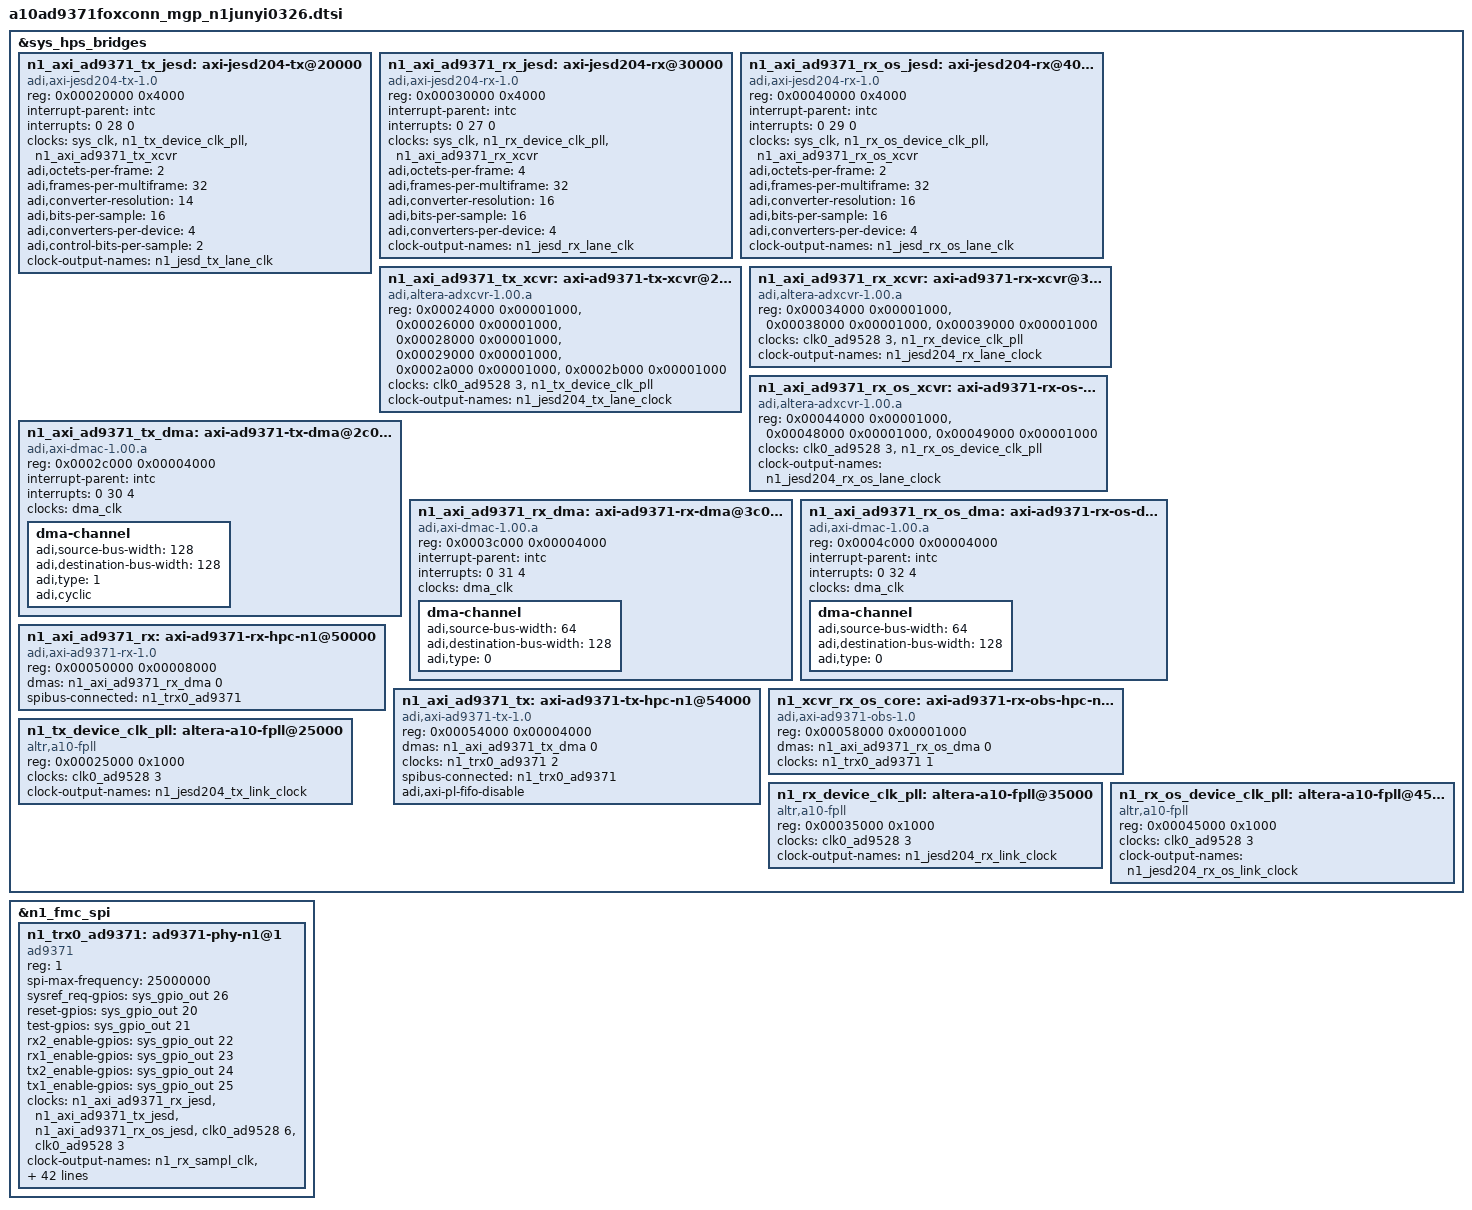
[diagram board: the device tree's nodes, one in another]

&sys_hps_bridges {

		/*n1_fmc_spi: spi@40 {
			compatible = "altr,spi-1.0";
			reg = <0x00000040 0x00000020>;
			interrupt-parent = <&intc>;
			interrupts = <0 26 4>;
			#address-cells = <0x1>;
			#size-cells = <0x0>;
		};*/

		n1_axi_ad9371_tx_jesd: axi-jesd204-tx@20000 {
			compatible = "adi,axi-jesd204-tx-1.0";
			reg = <0x00020000 0x4000>;

			interrupt-parent = <&intc>;
			interrupts = <0 28 0>;

			clocks = <&sys_clk>, <&n1_tx_device_clk_pll>, <&n1_axi_ad9371_tx_xcvr>;
			clock-names = "s_axi_aclk", "device_clk", "lane_clk";

			adi,octets-per-frame = <2>;
			adi,frames-per-multiframe = <32>;
			adi,converter-resolution = <14>;
			adi,bits-per-sample = <16>;
			adi,converters-per-device = <4>;
			adi,control-bits-per-sample = <2>;

			#clock-cells = <0>;
			clock-output-names = "n1_jesd_tx_lane_clk";
		};

		n1_axi_ad9371_rx_jesd: axi-jesd204-rx@30000 {
			compatible = "adi,axi-jesd204-rx-1.0";
			reg = <0x00030000 0x4000>;

			interrupt-parent = <&intc>;
			interrupts = <0 27 0>;

			clocks = <&sys_clk>, <&n1_rx_device_clk_pll>, <&n1_axi_ad9371_rx_xcvr>;
			clock-names = "s_axi_aclk", "device_clk", "lane_clk";

			adi,octets-per-frame = <4>;
			adi,frames-per-multiframe = <32>;
			adi,converter-resolution = <16>;
			adi,bits-per-sample = <16>;
			adi,converters-per-device = <4>;

			#clock-cells = <0>;
			clock-output-names = "n1_jesd_rx_lane_clk";
		};

		n1_axi_ad9371_rx_os_jesd: axi-jesd204-rx@40000 {
			compatible = "adi,axi-jesd204-rx-1.0";
			reg = <0x00040000 0x4000>;

			interrupt-parent = <&intc>;
			interrupts = <0 29 0>;

			clocks = <&sys_clk>, <&n1_rx_os_device_clk_pll>, <&n1_axi_ad9371_rx_os_xcvr>;
			clock-names = "s_axi_aclk", "device_clk", "lane_clk";

			adi,octets-per-frame = <2>;
			adi,frames-per-multiframe = <32>;
			adi,converter-resolution = <16>;
			adi,bits-per-sample = <16>;
			adi,converters-per-device = <4>;

			#clock-cells = <0>;
			clock-output-names = "n1_jesd_rx_os_lane_clk";
		};

		n1_axi_ad9371_tx_xcvr: axi-ad9371-tx-xcvr@24000 {
			compatible = "adi,altera-adxcvr-1.00.a";
			reg = <0x00024000 0x00001000>,
				<0x00026000 0x00001000>,
				<0x00028000 0x00001000>,
				<0x00029000 0x00001000>,
				<0x0002a000 0x00001000>,
				<0x0002b000 0x00001000>;
			reg-names = "adxcvr", "atx-pll", "adxcfg-0", "adxcfg-1", "adxcfg-2", "adxcfg-3";

			clocks = <&clk0_ad9528 3>, <&n1_tx_device_clk_pll>;
			clock-names = "ref", "link";

			#clock-cells = <0>;
			clock-output-names = "n1_jesd204_tx_lane_clock";
		};

		n1_axi_ad9371_rx_xcvr: axi-ad9371-rx-xcvr@34000 {
			compatible = "adi,altera-adxcvr-1.00.a";
			reg = <0x00034000 0x00001000>,
				<0x00038000 0x00001000>,
				<0x00039000 0x00001000>;
			reg-names = "adxcvr", "adxcfg-0", "adxcfg-1";

			clocks = <&clk0_ad9528 3>, <&n1_rx_device_clk_pll>;
			clock-names = "ref", "link";

			#clock-cells = <0>;
			clock-output-names = "n1_jesd204_rx_lane_clock";
		};

		n1_axi_ad9371_rx_os_xcvr: axi-ad9371-rx-os-xcvr@44000 {
			compatible = "adi,altera-adxcvr-1.00.a";
			reg = <0x00044000 0x00001000>,
				<0x00048000 0x00001000>,
				<0x00049000 0x00001000>;
			reg-names = "adxcvr", "adxcfg-0", "adxcfg-1";

			clocks = <&clk0_ad9528 3>, <&n1_rx_os_device_clk_pll>;
			clock-names = "ref", "link";

			#clock-cells = <0>;
			clock-output-names = "n1_jesd204_rx_os_lane_clock";
		};

		n1_axi_ad9371_tx_dma: axi-ad9371-tx-dma@2c000 {
			compatible = "adi,axi-dmac-1.00.a";
			reg = <0x0002c000 0x00004000>;
			interrupt-parent = <&intc>;
			interrupts = <0 30 4>;
			#dma-cells = <1>;
			clocks = <&dma_clk>;

			dma-channel {
				adi,source-bus-width = <128>;
				adi,destination-bus-width = <128>;
				adi,type = <1>;
				adi,cyclic;
			};
		};

		n1_axi_ad9371_rx_dma: axi-ad9371-rx-dma@3c000 {
			compatible = "adi,axi-dmac-1.00.a";
			reg = <0x0003c000 0x00004000>;
			interrupt-parent = <&intc>;
			interrupts = <0 31 4>;
			#dma-cells = <1>;
			clocks = <&dma_clk>;

			dma-channel {
				adi,source-bus-width = <64>;
				adi,destination-bus-width = <128>;
				adi,type = <0>;
			};
		};

		n1_axi_ad9371_rx_os_dma: axi-ad9371-rx-os-dma@4c000 {
			compatible = "adi,axi-dmac-1.00.a";
			reg = <0x0004c000 0x00004000>;
			interrupt-parent = <&intc>;
			interrupts = <0 32 4>;
			#dma-cells = <1>;
			clocks = <&dma_clk>;

			dma-channel {
				adi,source-bus-width = <64>;
				adi,destination-bus-width = <128>;
				adi,type = <0>;
			};
		};

		n1_axi_ad9371_rx: axi-ad9371-rx-hpc-n1@50000 {
			compatible = "adi,axi-ad9371-rx-1.0";
			reg = <0x00050000 0x00008000>;
			dmas = <&n1_axi_ad9371_rx_dma 0>;
			dma-names = "rx";
			spibus-connected = <&n1_trx0_ad9371>;
		};

		n1_axi_ad9371_tx: axi-ad9371-tx-hpc-n1@54000 {
			compatible = "adi,axi-ad9371-tx-1.0";
			reg = <0x00054000 0x00004000>;
			dmas = <&n1_axi_ad9371_tx_dma 0>;
			dma-names = "tx";
			clocks = <&n1_trx0_ad9371 2>;
			clock-names = "sampl_clk";
			spibus-connected = <&n1_trx0_ad9371>;
			//adi,axi-pl-fifo-enable;
			adi,axi-pl-fifo-disable;
		};

		n1_xcvr_rx_os_core: axi-ad9371-rx-obs-hpc-n1@58000 {
			compatible = "adi,axi-ad9371-obs-1.0";
			reg = <0x00058000 0x00001000>;
			dmas = <&n1_axi_ad9371_rx_os_dma 0>;
			dma-names = "rx";
			clocks = <&n1_trx0_ad9371 1>;
			clock-names = "sampl_clk";
		};

		n1_tx_device_clk_pll: altera-a10-fpll@25000 {
			compatible = "altr,a10-fpll";
			reg = <0x00025000 0x1000>;
			clocks = <&clk0_ad9528 3>;

			#clock-cells = <0>;
			clock-output-names = "n1_jesd204_tx_link_clock";
		};

		n1_rx_device_clk_pll: altera-a10-fpll@35000 {
			compatible = "altr,a10-fpll";
			reg = <0x00035000 0x1000>;
			clocks = <&clk0_ad9528 3>;

			#clock-cells = <0>;
			clock-output-names = "n1_jesd204_rx_link_clock";
		};

		n1_rx_os_device_clk_pll: altera-a10-fpll@45000 {
			compatible = "altr,a10-fpll";
			reg = <0x00045000 0x1000>;
			clocks = <&clk0_ad9528 3>;

			#clock-cells = <0>;
			clock-output-names = "n1_jesd204_rx_os_link_clock";
		};
};

&n1_fmc_spi {

	n1_trx0_ad9371: ad9371-phy-n1@1 {
		#address-cells = <1>;
		#size-cells = <0>;
		#clock-cells = <1>;
		compatible = "ad9371";

		reg = <1>;
		spi-max-frequency = <25000000>;

		sysref_req-gpios = <&sys_gpio_out 26 0>;
		reset-gpios = <&sys_gpio_out 20 0>;
		test-gpios = <&sys_gpio_out 21 0>;
		rx2_enable-gpios = <&sys_gpio_out 22 0>;
		rx1_enable-gpios = <&sys_gpio_out 23 0>;
		tx2_enable-gpios = <&sys_gpio_out 24 0>;
		tx1_enable-gpios = <&sys_gpio_out 25 0>;

		clocks = <&n1_axi_ad9371_rx_jesd>, <&n1_axi_ad9371_tx_jesd>, <&n1_axi_ad9371_rx_os_jesd>, <&clk0_ad9528 6>, <&clk0_ad9528 3>;
		clock-names = "jesd_rx_clk", "jesd_tx_clk", "jesd_rx_os_clk", "dev_clk", "fmc_clk";
		clock-output-names = "n1_rx_sampl_clk", "n1_rx_os_sampl_clk", "n1_tx_sampl_clk";

		adi,clocks-clk-pll-vco-freq_khz = <9830400>;
		adi,clocks-device-clock_khz = <122880>;
		adi,clocks-clk-pll-hs-div = <4>;
		adi,clocks-clk-pll-vco-div = <2>;

		adi,jesd204-obs-framer-over-sample = <0>;

		adi,rx-profile-adc-div = <1>;
		adi,rx-profile-en-high-rej-dec5 = <1>;
		adi,rx-profile-iq-rate_khz = <30720>;
		adi,rx-profile-rf-bandwidth_hz = <20000000>;
		adi,rx-profile-rhb1-decimation = <2>;
		adi,rx-profile-rx-bbf-3db-corner_khz = <20000>;
		adi,rx-profile-rx-dec5-decimation = <5>;
		adi,rx-profile-rx-fir-decimation = <4>;

		adi,obs-profile-adc-div = <1>;
		adi,obs-profile-en-high-rej-dec5 = <1>;
		adi,obs-profile-iq-rate_khz = <61440>;
		adi,obs-profile-rf-bandwidth_hz = <20000000>;
		adi,obs-profile-rhb1-decimation = <2>;
		adi,obs-profile-rx-bbf-3db-corner_khz = <20000>;
		adi,obs-profile-rx-dec5-decimation = <5>;
		adi,obs-profile-rx-fir-decimation = <2>;

		adi,tx-profile-dac-div = <1>;
		adi,tx-profile-iq-rate_khz = <61440>;
		adi,tx-profile-primary-sig-bandwidth_hz = <20000000>;
		adi,tx-profile-rf-bandwidth_hz = <20000000>;
		adi,tx-profile-thb1-interpolation = <2>;
		adi,tx-profile-thb2-interpolation = <2>;
		adi,tx-profile-tx-bbf-3db-corner_khz = <20000>;
		adi,tx-profile-tx-dac-3db-corner_khz = <92000>;
		adi,tx-profile-tx-fir-interpolation = <2>;
		adi,tx-profile-tx-input-hb-interpolation = <1>;

		adi,sniffer-profile-adc-div = <1>;
		adi,sniffer-profile-en-high-rej-dec5 = <1>;
		adi,sniffer-profile-iq-rate_khz = <30720>;
		adi,sniffer-profile-rf-bandwidth_hz = <20000000>;
		adi,sniffer-profile-rhb1-decimation = <2>;
		adi,sniffer-profile-rx-bbf-3db-corner_khz = <20000>;
		adi,sniffer-profile-rx-dec5-decimation = <5>;
		adi,sniffer-profile-rx-fir-decimation = <4>;
	};
};

